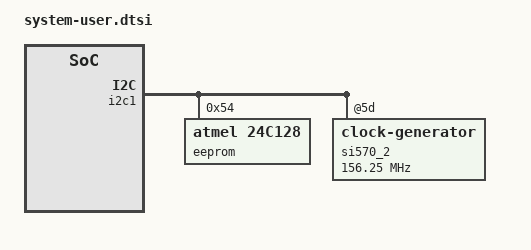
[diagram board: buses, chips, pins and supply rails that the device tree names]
/include/ "system-conf.dtsi"
/ {
	chosen {
		bootargs = " earlycon console=ttyPS0,115200 clk_ignore_unused root=/dev/ram0 rw";
		stdout-path = "serial0:115200n8";
		xlnx,eeprom = &eeprom;
	};
};
&i2c1 {
	i2c-mux@74 {
		i2c_eeprom: i2c@0 {
			eeprom: eeprom@54 {
				#address-cells = <1>;
				#size-cells = <1>;
				compatible = "atmel,24c128";
				reg = <0x54>;
				mac_address: mac-address@20 {
					reg = <0x20 6>;
				};
			};
		};
		i2c_si570_mgt: i2c@3 {
			si570_2: clock-generator@5d { /* USER MGT SI570 - u48 */
				clock-frequency = <156250000>;
			};
		};
	};
};
&gem3 {
	nvmem-cells = <&mac_address>;
	nvmem-cell-names = "mac-address";
};
&axiLite1 { /* Prevent memory overlap with usp_rf_data_converter */
	status = "disabled";
};
/ {
	axi_stream_dma_0@b0000000 {
		compatible = "axi_stream_dma";
		reg = <0x0 0xb0000000 0x0 0x10000>;
		interrupts = <0 89 4>;
		interrupt-parent = <&gic>;
	};
	usp_rf_data_converter@490000000 {
		compatible = "xlnx,usp-rf-data-converter-2.6";
		num-insts = <0x1>;
		param-list = [ 00 00 00 00 00 00 08 b0 00 00 00 00 01 00 00 00 00 00 00 00 00 00 00 00 01 00 00 00 01 00 00 00 00 00 00 00 01 00 00 00 01 00 00 00 00 00 00 00 9a 99 99 99 99 99 19 40 00 00 00 00 00 00 b9 40 00 00 00 00 00 00 79 40 0a 00 00 00 02 00 00 00 01 00 00 00 00 00 00 00 9e ef a7 c6 4b 37 1a 40 04 00 00 00 00 00 00 00 01 00 00 00 00 00 00 00 02 00 00 00 00 00 00 00 00 00 00 00 00 00 00 00 02 00 00 00 00 00 00 00 00 00 00 00 00 00 00 00 02 00 00 00 00 00 00 00 00 00 00 00 00 00 00 00 02 00 00 00 00 00 00 00 00 00 00 00 10 00 00 00 01 00 00 00 00 00 00 00 00 00 00 00 00 00 00 00 00 00 00 00 00 00 00 00 00 00 00 00 10 00 00 00 00 00 00 00 00 00 00 00 00 00 00 00 03 00 00 00 00 00 00 00 00 00 00 00 00 00 00 00 10 00 00 00 00 00 00 00 00 00 00 00 00 00 00 00 03 00 00 00 00 00 00 00 00 00 00 00 00 00 00 00 10 00 00 00 00 00 00 00 00 00 00 00 00 00 00 00 03 00 00 00 00 00 00 00 00 00 00 00 00 00 00 00 00 00 00 00 9a 99 99 99 99 99 19 40 00 00 00 00 00 00 b9 40 00 00 00 00 00 00 00 00 0a 00 00 00 02 00 00 00 01 00 00 00 00 00 00 00 9e ef a7 c6 4b 37 1a 40 04 00 00 00 00 00 00 00 00 00 00 00 00 00 00 00 02 00 00 00 00 00 00 00 00 00 00 00 00 00 00 00 02 00 00 00 00 00 00 00 00 00 00 00 00 00 00 00 02 00 00 00 00 00 00 00 00 00 00 00 00 00 00 00 02 00 00 00 00 00 00 00 00 00 00 00 10 00 00 00 00 00 00 00 00 00 00 00 00 00 00 00 03 00 00 00 00 00 00 00 00 00 00 00 00 00 00 00 10 00 00 00 00 00 00 00 00 00 00 00 00 00 00 00 03 00 00 00 00 00 00 00 00 00 00 00 00 00 00 00 10 00 00 00 00 00 00 00 00 00 00 00 00 00 00 00 03 00 00 00 00 00 00 00 00 00 00 00 00 00 00 00 10 00 00 00 00 00 00 00 00 00 00 00 00 00 00 00 03 00 00 00 00 00 00 00 00 00 00 00 00 00 00 00 00 00 00 00 9a 99 99 99 99 99 19 40 00 00 00 00 00 00 b9 40 00 00 00 00 00 00 00 00 0a 00 00 00 02 00 00 00 01 00 00 00 00 00 00 00 9e ef a7 c6 4b 37 1a 40 00 00 00 00 00 00 00 00 00 00 00 00 00 00 00 00 02 00 00 00 00 00 00 00 00 00 00 00 00 00 00 00 02 00 00 00 00 00 00 00 00 00 00 00 00 00 00 00 02 00 00 00 00 00 00 00 00 00 00 00 00 00 00 00 02 00 00 00 00 00 00 00 00 00 00 00 10 00 00 00 00 00 00 00 00 00 00 00 00 00 00 00 03 00 00 00 00 00 00 00 00 00 00 00 00 00 00 00 10 00 00 00 00 00 00 00 00 00 00 00 00 00 00 00 03 00 00 00 00 00 00 00 00 00 00 00 00 00 00 00 10 00 00 00 00 00 00 00 00 00 00 00 00 00 00 00 03 00 00 00 00 00 00 00 00 00 00 00 00 00 00 00 10 00 00 00 00 00 00 00 00 00 00 00 00 00 00 00 03 00 00 00 00 00 00 00 00 00 00 00 00 00 00 00 00 00 00 00 9a 99 99 99 99 99 19 40 00 00 00 00 00 00 b9 40 00 00 00 00 00 00 00 00 0a 00 00 00 02 00 00 00 01 00 00 00 00 00 00 00 9e ef a7 c6 4b 37 1a 40 00 00 00 00 00 00 00 00 00 00 00 00 00 00 00 00 02 00 00 00 00 00 00 00 00 00 00 00 00 00 00 00 02 00 00 00 00 00 00 00 00 00 00 00 00 00 00 00 02 00 00 00 00 00 00 00 00 00 00 00 00 00 00 00 02 00 00 00 00 00 00 00 00 00 00 00 10 00 00 00 00 00 00 00 00 00 00 00 00 00 00 00 03 00 00 00 00 00 00 00 00 00 00 00 00 00 00 00 10 00 00 00 00 00 00 00 00 00 00 00 00 00 00 00 03 00 00 00 00 00 00 00 00 00 00 00 00 00 00 00 10 00 00 00 00 00 00 00 00 00 00 00 00 00 00 00 03 00 00 00 00 00 00 00 00 00 00 00 00 00 00 00 10 00 00 00 00 00 00 00 00 00 00 00 00 00 00 00 03 00 00 00 00 00 00 00 00 00 00 00 01 00 00 00 00 00 00 00 00 00 00 00 00 00 00 40 00 00 00 00 00 40 9f 40 00 00 00 00 00 40 6f 40 0a 00 00 00 06 00 00 00 01 00 00 00 00 00 00 00 fc a9 f1 d2 4d 62 10 40 02 00 00 00 01 00 00 00 02 00 00 00 01 00 00 00 02 00 00 00 00 00 00 00 02 00 00 00 00 00 00 00 02 00 00 00 00 00 00 00 08 00 00 00 01 00 00 00 00 00 00 00 00 00 00 00 00 00 00 00 00 00 00 00 00 00 00 00 08 00 00 00 01 00 00 00 00 00 00 00 00 00 00 00 00 00 00 00 00 00 00 00 00 00 00 00 08 00 00 00 00 00 00 00 00 00 00 00 03 00 00 00 00 00 00 00 00 00 00 00 00 00 00 00 08 00 00 00 00 00 00 00 00 00 00 00 03 00 00 00 00 00 00 00 00 00 00 00 00 00 00 00 00 00 00 00 00 00 00 00 00 00 00 40 00 00 00 00 00 40 9f 40 00 00 00 00 00 00 00 00 0a 00 00 00 06 00 00 00 01 00 00 00 00 00 00 00 fc a9 f1 d2 4d 62 10 40 02 00 00 00 00 00 00 00 02 00 00 00 00 00 00 00 02 00 00 00 00 00 00 00 02 00 00 00 00 00 00 00 02 00 00 00 00 00 00 00 08 00 00 00 00 00 00 00 00 00 00 00 03 00 00 00 00 00 00 00 00 00 00 00 00 00 00 00 08 00 00 00 00 00 00 00 00 00 00 00 03 00 00 00 00 00 00 00 00 00 00 00 00 00 00 00 08 00 00 00 00 00 00 00 00 00 00 00 03 00 00 00 00 00 00 00 00 00 00 00 00 00 00 00 08 00 00 00 00 00 00 00 00 00 00 00 03 00 00 00 00 00 00 00 00 00 00 00 00 00 00 00 00 00 00 00 00 00 00 00 00 00 00 40 00 00 00 00 00 40 9f 40 00 00 00 00 00 00 00 00 0a 00 00 00 06 00 00 00 01 00 00 00 00 00 00 00 fc a9 f1 d2 4d 62 10 40 02 00 00 00 00 00 00 00 02 00 00 00 00 00 00 00 02 00 00 00 00 00 00 00 02 00 00 00 00 00 00 00 02 00 00 00 00 00 00 00 08 00 00 00 00 00 00 00 00 00 00 00 03 00 00 00 00 00 00 00 00 00 00 00 00 00 00 00 08 00 00 00 00 00 00 00 00 00 00 00 03 00 00 00 00 00 00 00 00 00 00 00 00 00 00 00 08 00 00 00 00 00 00 00 00 00 00 00 03 00 00 00 00 00 00 00 00 00 00 00 00 00 00 00 08 00 00 00 00 00 00 00 00 00 00 00 03 00 00 00 00 00 00 00 00 00 00 00 00 00 00 00 00 00 00 00 00 00 00 00 00 00 00 40 00 00 00 00 00 40 9f 40 00 00 00 00 00 00 00 00 0a 00 00 00 06 00 00 00 01 00 00 00 00 00 00 00 fc a9 f1 d2 4d 62 10 40 02 00 00 00 00 00 00 00 02 00 00 00 00 00 00 00 02 00 00 00 00 00 00 00 02 00 00 00 00 00 00 00 02 00 00 00 00 00 00 00 08 00 00 00 00 00 00 00 00 00 00 00 03 00 00 00 00 00 00 00 00 00 00 00 00 00 00 00 08 00 00 00 00 00 00 00 00 00 00 00 03 00 00 00 00 00 00 00 00 00 00 00 00 00 00 00 08 00 00 00 00 00 00 00 00 00 00 00 03 00 00 00 00 00 00 00 00 00 00 00 00 00 00 00 08 00 00 00 00 00 00 00 00 00 00 00 03 00 00 00 00 00 00 00 00 00 00 00];
		reg = <0x4 0x90000000 0x0 0x40000>;
	};
};
